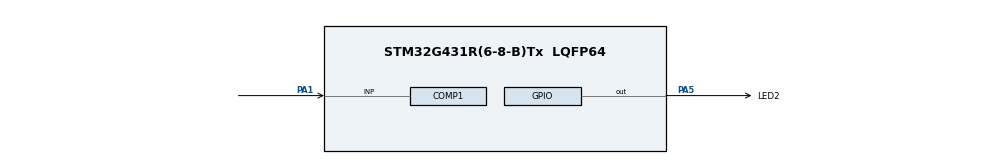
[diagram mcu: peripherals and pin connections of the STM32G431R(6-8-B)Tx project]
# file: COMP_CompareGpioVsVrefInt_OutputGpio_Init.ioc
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COMP1.BlankingSrce=COMP_BLANKINGSRC_NONE
COMP1.Hysteresis=COMP_HYSTERESIS_NONE
COMP1.OutputPol=COMP_OUTPUTPOL_NONINVERTED
COMP1.TriggerMode=COMP_TRIGGERMODE_NONE
Mcu.Family=STM32G4
Mcu.Name=STM32G431R(6-8-B)Tx
Mcu.Package=LQFP64
NVIC.PriorityGroup=NVIC_PRIORITYGROUP_4
PA1.Mode=INP
PA1.Signal=COMP1_INP
PA5.GPIO_Label=LED2
PA5.Signal=GPIO_Output
ProjectManager.HeapSize=0x200
ProjectManager.StackSize=0x400
ProjectManager.TargetToolchain=EWARM V8.32
RCC.ADC12Freq_Value=150000000
RCC.AHBFreq_Value=150000000
RCC.APB1Freq_Value=150000000
RCC.APB1TimFreq_Value=150000000
RCC.APB2Freq_Value=150000000
RCC.APB2TimFreq_Value=150000000
RCC.CortexFreq_Value=150000000
RCC.EXTERNAL_CLOCK_VALUE=12288000
RCC.HCLKFreq_Value=150000000
RCC.HSE_VALUE=24000000
RCC.HSI48_VALUE=48000000
RCC.HSI_VALUE=16000000
RCC.LSE_VALUE=32768
RCC.PLLM=RCC_PLLM_DIV4
RCC.PLLN=75
RCC.SYSCLKFreq_VALUE=150000000
RCC.SYSCLKSource=RCC_SYSCLKSOURCE_PLLCLK
RCC.USBFreq_Value=150000000
RCC.VCOOutputFreq_Value=300000000
VP_COMP1_VS_VREFINT.Mode=VREFINT
VP_SYS_VS_DBSignals.Mode=DisableDeadBatterySignals
board=custom

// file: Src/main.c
/* USER CODE BEGIN Header */
/**
  ******************************************************************************
  * @file    Examples_LL/COMP/COMP_CompareGpioVsVrefInt_OutputGpio_Init/Src/main.c
  * @author  MCD Application Team
  * @brief   This example shows how to use a comparator peripheral
  *          to compare a voltage level applied on a GPIO pin
  *          versus the internal voltage reference (VrefInt),
  *          comparator output is connected to a GPIO.
  *          This example is based on the STM32G4xx COMP LL API;
  *          Peripheral initialization done using LL unitary services functions.
  ******************************************************************************
  * @attention
  *
  * <h2><center>&copy; Copyright (c) 2019 STMicroelectronics.
  * All rights reserved.</center></h2>
  *
  * This software component is licensed by ST under BSD 3-Clause license,
  * the "License"; You may not use this file except in compliance with the
  * License. You may obtain a copy of the License at:
  *                        opensource.org/licenses/BSD-3-Clause
  *
  ******************************************************************************
  */
/* USER CODE END Header */

#include "main.h"

void SystemClock_Config(void);
static void MX_GPIO_Init(void);
static void MX_COMP1_Init(void);
/* USER CODE BEGIN PFP */
void     Activate_COMP(void);
void     LED_On(void);
void     LED_Off(void);

/* USER CODE END PFP */

int main(void)
{

  /* MCU Configuration--------------------------------------------------------*/

  /* Reset of all peripherals, Initializes the Flash interface and the Systick. */

  LL_APB2_GRP1_EnableClock(LL_APB2_GRP1_PERIPH_SYSCFG);
  LL_APB1_GRP1_EnableClock(LL_APB1_GRP1_PERIPH_PWR);

  NVIC_SetPriorityGrouping(NVIC_PRIORITYGROUP_4);

  /* System interrupt init*/

  /** Disable the internal Pull-Up in Dead Battery pins of UCPD peripheral
  */
  LL_PWR_DisableDeadBatteryPD();

  /* Configure the system clock */
  SystemClock_Config();

  /* Initialize all configured peripherals */
  MX_GPIO_Init();
  MX_COMP1_Init();
  /* USER CODE BEGIN 2 */

  /* Activate comparator */
  Activate_COMP();

  /* Lock comparator instance */
  //LL_COMP_Lock(COMP1);

  /* USER CODE END 2 */

  /* Infinite loop */
  /* USER CODE BEGIN WHILE */
  while (1)
  {
    /* Set LED state in function of state of GPIO connected to                */
    /* comparator output.                                                     */
    /* Note: State of GPIO is monitored for the purpose of this example.      */
    /*       An alternate solution is to monitor directly comparator output   */
    /*       using function "LL_COMP_ReadOutputLevel()".                      */
    if (LL_GPIO_IsInputPinSet(GPIOA, LL_GPIO_PIN_0) != 0)
    {
      LED_On();
    }
    else
    {
      LED_Off();
    }
    /* USER CODE END WHILE */

  }
}

void SystemClock_Config(void)
{
  LL_FLASH_SetLatency(LL_FLASH_LATENCY_7);

   if(LL_FLASH_GetLatency() != LL_FLASH_LATENCY_7)
  {
    Error_Handler();
  }
  LL_PWR_SetRegulVoltageScaling(LL_PWR_REGU_VOLTAGE_SCALE1);
  LL_RCC_HSI_Enable();

   /* Wait till HSI is ready */
  while(LL_RCC_HSI_IsReady() != 1)
  {

  }
  LL_RCC_HSI_SetCalibTrimming(64);
  LL_RCC_PLL_ConfigDomain_SYS(LL_RCC_PLLSOURCE_HSI, LL_RCC_PLLM_DIV_4, 75, LL_RCC_PLLR_DIV_2);
  LL_RCC_PLL_EnableDomain_SYS();
  LL_RCC_PLL_Enable();

   /* Wait till PLL is ready */
  while(LL_RCC_PLL_IsReady() != 1)
  {

  }
  LL_RCC_SetSysClkSource(LL_RCC_SYS_CLKSOURCE_PLL);
  LL_RCC_SetAHBPrescaler(LL_RCC_SYSCLK_DIV_2);

   /* Wait till System clock is ready */
  while(LL_RCC_GetSysClkSource() != LL_RCC_SYS_CLKSOURCE_STATUS_PLL)
  {

  }
  /* Insure 1µs transition state at intermediate medium speed clock based on DWT */
  CoreDebug->DEMCR |= CoreDebug_DEMCR_TRCENA_Msk;
  DWT->CTRL |= DWT_CTRL_CYCCNTENA_Msk;
  DWT->CYCCNT = 0;
  while(DWT->CYCCNT < 100);
  /* Set AHB prescaler*/
  LL_RCC_SetAHBPrescaler(LL_RCC_SYSCLK_DIV_1);
  LL_RCC_SetAPB1Prescaler(LL_RCC_APB1_DIV_1);
  LL_RCC_SetAPB2Prescaler(LL_RCC_APB1_DIV_1);

  LL_Init1msTick(150000000);

  LL_SetSystemCoreClock(150000000);
}

static void MX_COMP1_Init(void)
{

  LL_COMP_InitTypeDef COMP_InitStruct = {0};

  LL_GPIO_InitTypeDef GPIO_InitStruct = {0};

  LL_AHB2_GRP1_EnableClock(LL_AHB2_GRP1_PERIPH_GPIOA);
  /**COMP1 GPIO Configuration
  PA1   ------> COMP1_INP
  */
  GPIO_InitStruct.Pin = LL_GPIO_PIN_1;
  GPIO_InitStruct.Mode = LL_GPIO_MODE_ANALOG;
  GPIO_InitStruct.Pull = LL_GPIO_PULL_NO;
  LL_GPIO_Init(GPIOA, &GPIO_InitStruct);

  /* USER CODE BEGIN COMP1_Init 1 */
  /* Configure GPIO connected to the comparator output */
  /* Note: Other GPIO are available as comparator output,                     */
  /*       refer to device datasheet.                                         */
  /* Enable GPIO clock */
  LL_AHB2_GRP1_EnableClock(LL_AHB2_GRP1_PERIPH_GPIOA);

  /* Configure GPIO output type */
  LL_GPIO_SetPinOutputType(GPIOA, LL_GPIO_PIN_0, LL_GPIO_OUTPUT_PUSHPULL);

  /* Configure GPIO speed */
  LL_GPIO_SetPinSpeed(GPIOA, LL_GPIO_PIN_0, LL_GPIO_SPEED_FREQ_HIGH);

  /* Configure GPIO in alternate function mode to be used as COMP output */
  LL_GPIO_SetPinMode(GPIOA, LL_GPIO_PIN_0, LL_GPIO_MODE_ALTERNATE);
  LL_GPIO_SetAFPin_0_7(GPIOA, LL_GPIO_PIN_0, LL_GPIO_AF_8);

  /* USER CODE END COMP1_Init 1 */
  COMP_InitStruct.InputPlus = LL_COMP_INPUT_PLUS_IO1;
  COMP_InitStruct.InputMinus = LL_COMP_INPUT_MINUS_VREFINT;
  COMP_InitStruct.InputHysteresis = LL_COMP_HYSTERESIS_NONE;
  COMP_InitStruct.OutputPolarity = LL_COMP_OUTPUTPOL_NONINVERTED;
  COMP_InitStruct.OutputBlankingSource = LL_COMP_BLANKINGSRC_NONE;
  LL_COMP_Init(COMP1, &COMP_InitStruct);

  /* Wait loop initialization and execution */
  /* Note: Variable divided by 2 to compensate partially CPU processing cycles */
  __IO uint32_t wait_loop_index = 0;
  wait_loop_index = (LL_COMP_DELAY_VOLTAGE_SCALER_STAB_US * (SystemCoreClock / (1000000 * 2)));
  while(wait_loop_index != 0)
  {
    wait_loop_index--;
  }
  LL_EXTI_DisableEvent_0_31(LL_EXTI_LINE_21);
  LL_EXTI_DisableIT_0_31(LL_EXTI_LINE_21);

}

static void MX_GPIO_Init(void)
{
  LL_GPIO_InitTypeDef GPIO_InitStruct = {0};

  /* GPIO Ports Clock Enable */
  LL_AHB2_GRP1_EnableClock(LL_AHB2_GRP1_PERIPH_GPIOA);

  /**/
  LL_GPIO_ResetOutputPin(LED2_GPIO_Port, LED2_Pin);

  /**/
  GPIO_InitStruct.Pin = LED2_Pin;
  GPIO_InitStruct.Mode = LL_GPIO_MODE_OUTPUT;
  GPIO_InitStruct.Speed = LL_GPIO_SPEED_FREQ_LOW;
  GPIO_InitStruct.OutputType = LL_GPIO_OUTPUT_PUSHPULL;
  GPIO_InitStruct.Pull = LL_GPIO_PULL_NO;
  LL_GPIO_Init(LED2_GPIO_Port, &GPIO_InitStruct);

}

/* USER CODE BEGIN 4 */
/**
  * @brief  Perform comparator activation procedure
  *         (COMP instance: COMP1).
  * @note   Operations:
  *         - Enable comparator instance
  *         - Wait for comparator startup time
  *           (required to reach propagation delay specification)
  * @param  None
  * @retval None
  */
void Activate_COMP(void)
{
  __IO uint32_t wait_loop_index = 0;

  /* Enable comparator */
  LL_COMP_Enable(COMP1);

  /* Delay for comparator startup time.                                       */
  /* Compute number of CPU cycles to wait for, from delay in us.              */
  /* Note: Variable divided by 2 to compensate partially                      */
  /*       CPU processing cycles (depends on compilation optimization).       */
  /* Note: If system core clock frequency is below 200kHz, wait time          */
  /*       is only a few CPU processing cycles.                               */
  wait_loop_index = ((LL_COMP_DELAY_STARTUP_US * (SystemCoreClock / (100000 * 2))) / 10);
  while(wait_loop_index != 0)
  {
    wait_loop_index--;
  }
}
/**
  * @brief  Turn-on LED2.
  * @param  None
  * @retval None
  */
void LED_On(void)
{
  /* Turn LED2 on */
  LL_GPIO_SetOutputPin(LED2_GPIO_Port, LED2_Pin);
}

/**
  * @brief  Turn-off LED2.
  * @param  None
  * @retval None
  */
void LED_Off(void)
{
  /* Turn LED2 off */
  LL_GPIO_ResetOutputPin(LED2_GPIO_Port, LED2_Pin);
}

/* USER CODE END 4 */

void Error_Handler(void)
{
}

/************************ (C) COPYRIGHT STMicroelectronics *****END OF FILE****/
